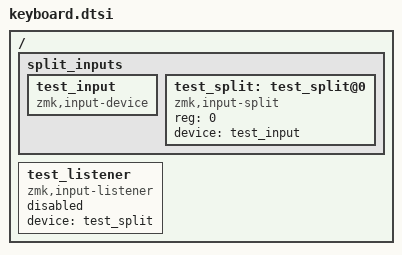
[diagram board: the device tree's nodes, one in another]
/ {
    split_inputs {
        #address-cells = <1>;
        #size-cells = <0>;

        // Primeiro definimos o input device
        test_input: test_input {
            compatible = "zmk,input-device";
        };

        // Depois podemos referenciar ele no split
        test_split: test_split@0 {
            compatible = "zmk,input-split";
            reg = <0>;
            device = <&test_input>;
        };
    };

    test_listener: test_listener {
        compatible = "zmk,input-listener";
        status = "disabled"; // ativaremos no overlay
        device = <&test_split>; // obrigatório!
    };
};
